# TREMO register map
File version: 1.6.2
CPU: CM4 r0p1, little endian, MPU, FPU, 3 interrupt priority bits
Registers are 32-bit, read-write, reset 0x0 unless marked. A register's access mark holds for its fields unless they carry their own. Offsets are from the block's base; [hi:lo] are bit positions; {n}, {i} and the like mark numbered series.

## TIMER0 — Timer
Base 0x4000A000
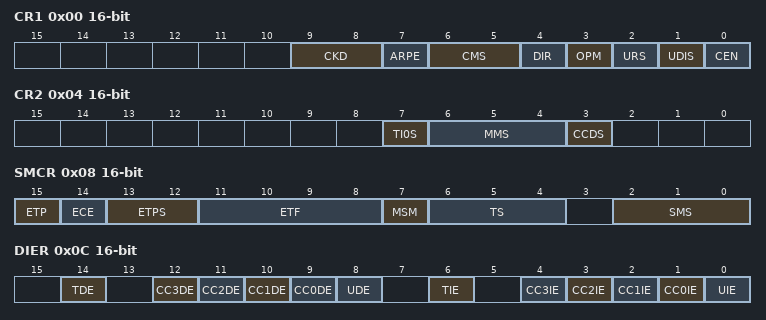
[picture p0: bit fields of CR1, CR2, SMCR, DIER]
0x00 CR1 16-bit — TIMER control register 1
  [9:8] CKD — sampling clock divider
  [7] ARPE — shadow reload register enable
  [6:5] CMS — counting mode selection
  [4] DIR — Count direction
  [3] OPM — One Pulse Mode
  [2] URS — Update Request Source
  [1] UDIS — Update disable
  [0] CEN — Counter enable
0x04 CR2 16-bit — TIMER control register 2
  [7] TI0S — channel 0/1 source Select
  [6:4] MMS — mode selection
  [3] CCDS — DMA request source selection
0x08 SMCR 16-bit (reset mask 0x7F) — TIMER slave Mode Control register
  [15] ETP — External trigger polarity selection
  [14] ECE — External clock mode 2 enable
  [13:12] ETPS — External trigger input frequency division
  [11:8] ETF — External trigger input filter configuration
  [7] MSM — Master-slave synchronization mode
  [6:4] TS — Trigger source selection
  [2:0] SMS — slave mode select
0x0C DIER 16-bit — TIMER DMA/interrupt enable register
  [14] TDE — Trigger event DMA request enable
  [n+9] CC{n}DE (n=0..3) — Channel {n} event DMA request enable
  [8] UDE — Update event DMA request enable
  [6] TIE — Trigger event interrupt enable
  [4] CC3IE — Capture/Compare 3 interrupt enable
  [3] CC2IE — Capture/Compare 2 interrupt enable
  [2] CC1IE — Capture/Compare 1 interrupt enable
  [1] CC0IE — Channel 0 event interrupt enable
  [0] UIE — Update interrupt enable
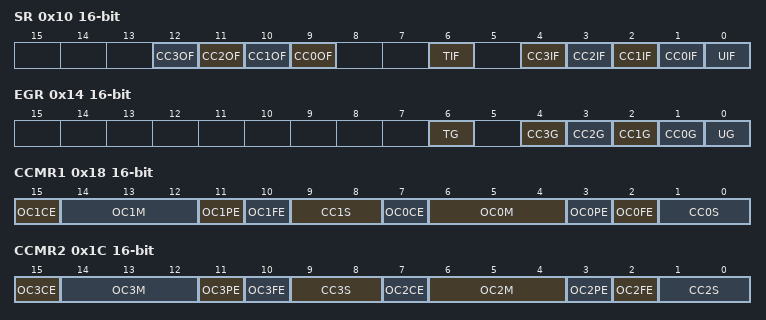
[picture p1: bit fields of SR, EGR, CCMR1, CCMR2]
0x10 SR 16-bit — status register
  [n+9] CC{n}OF (n=0..3) — Capture {n} overcapture flag
  [6] TIF — Trigger interrupt flag
  [n+1] CC{n}IF (n=0..3) — Capture/Compare {n} interrupt flag
  [0] UIF — Update interrupt flag
0x14 EGR 16-bit wo — TIMER event generation register
  [6] TG — Trigger event generation enable
  [n+1] CC{n}G (n=0..3) — Channel {n} capture/compare event generation enable
  [0] UG — Update event generation enable
0x18 CCMR1 16-bit — capture/compare mode register 1
  [15] OC1CE — Channel 1 output compare clear enable
  [14:12] OC1M — Channel 1 output compare mode selection
  [11] OC1PE — Channel 1 output compare shadow register enable
  [10] OC1FE — Channel 1 fast output enable
  [9:8] CC1S — Channel 1 capture/compare selection
  [7] OC0CE — Channel 0 output compare clear enable
  [6:4] OC0M — Channel 0 output compare mode selection
  [3] OC0PE — Channel 0 output compare shadow register enable
  [2] OC0FE — Channel 0 fast output enable
  [1:0] CC0S — Channel 0 capture/compare selection
0x1C CCMR2 16-bit — capture/compare mode register 2
  [15] OC3CE — Channel 3 output compare clear enable
  [14:12] OC3M — Channel 3 output compare mode selection
  [11] OC3PE — Channel 3 output compare shadow register enable
  [10] OC3FE — Channel 3 fast output enable
  [9:8] CC3S — Channel 3 capture/compare selection
  [7] OC2CE — Channel 0 output compare clear enable
  [6:4] OC2M — Channel 2 output compare mode selection
  [3] OC2PE — Channel 2 output compare shadow register enable
  [2] OC2FE — Channel 2 fast output enable
  [1:0] CC2S — Channel 2 capture/compare selection
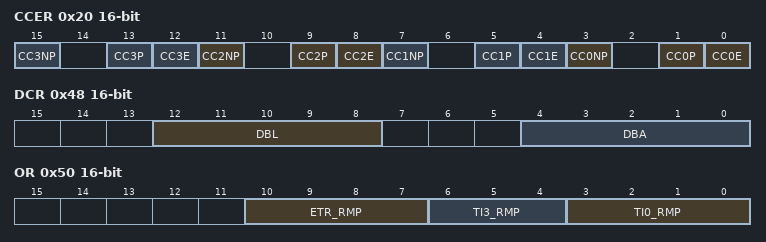
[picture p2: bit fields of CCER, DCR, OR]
0x20 CCER 16-bit — TIMER capture/compare enable register
  [4n+3] CC{n}NP (n=0..3) — Channel {n} input enable
  [4n+1] CC{n}P (n=0..3) — Channel {n} output polarity
  [4n] CC{n}E (n=0..3) — Channel {n} enable
0x24 CNT 16-bit — TIMER counter register
  [15:0] CNT — Count value
0x28 PSC 16-bit — TIMER prescaler register
  [15:0] PSC — Prescaler value
0x2C ARR — TIMER auto-reload register
  [15:0] ARR — Counter reload value
0x34 CCR0 16-bit — Channel 0 capture/compare register
  [15:0] CCR — Channel 0 capture/compare value
0x38 CCR1 16-bit — Channel 1 capture/compare register
  [15:0] CCR — Channel 1 capture/compare value
0x3C CCR2 16-bit — Channel 2 capture/compare register
  [15:0] CCR — Channel 1 capture/compare value
0x40 CCR3 16-bit — Channel 3 capture/compare register
  [15:0] CCR — Channel 3 capture/compare value
0x48 DCR 16-bit — DMA control register
  [12:8] DBL — DMA continuous read and write length
  [4:0] DBA — DMA continuously reads and writes base address
0x4C DMAR 16-bit — TIMER DMA address for full transfer register
  [15:0] DMAR — This register holds the value of the register for the current DMA operation
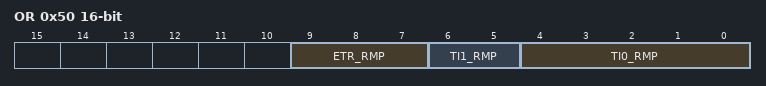
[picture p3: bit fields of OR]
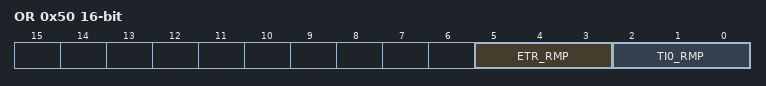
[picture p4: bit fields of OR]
0x50 OR 16-bit — Option register
  [10:7] ETR_RMP — ETR remapping
  [6:4] TI3_RMP — Channel 3 remapping
  [3:0] TI0_RMP — Channel 0 remapping

## TIMER1 — Timer
Base 0x4001A000
Registers as TIMER0; these are added or differ:
0x50 OR 16-bit — Option register
  [1:0] TI2_RMP — Channel 2 remapping

## TIMER2 — Timer
Base 0x4000B000
Registers as TIMER0; these are added or differ:
0x50 OR 16-bit — Option register
  [9:7] ETR_RMP — ETR remapping
  [6:5] TI1_RMP — Channel 1 remapping
  [4:0] TI0_RMP — Channel 0 remapping

## TIMER3 — Timer
Base 0x4001B000
Registers as TIMER0; these are added or differ:
0x50 OR 16-bit — Option register
  [5:3] ETR_RMP — Channel 1 remapping
  [2:0] TI0_RMP — Channel 0 remapping
